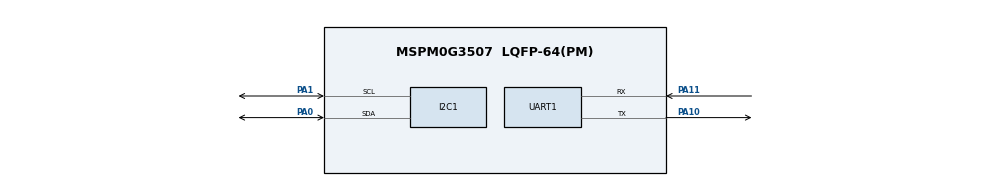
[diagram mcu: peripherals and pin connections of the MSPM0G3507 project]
/**
 * These arguments were used when this file was generated. They will be automatically applied on subsequent loads
 * via the GUI or CLI. Run CLI with '--help' for additional information on how to override these arguments.
 * @cliArgs --device "MSPM0G350X" --part "Default" --package "LQFP-64(PM)" --product "mspm0_sdk@2.10.00.04"
 * @v2CliArgs --device "MSPM0G3507" --package "LQFP-64(PM)" --product "mspm0_sdk@2.10.00.04"
 * @versions {"tool":"1.26.2+4477"}
 */

/**
 * Import the modules used in this configuration.
 */
const GPIO   = scripting.addModule("/ti/driverlib/GPIO", {}, false);
const GPIO1  = GPIO.addInstance();
const GPIO2  = GPIO.addInstance();
const GPIO3  = GPIO.addInstance();
const GPIO4  = GPIO.addInstance();
const I2C    = scripting.addModule("/ti/driverlib/I2C", {}, false);
const I2C1   = I2C.addInstance();
const SYSCTL = scripting.addModule("/ti/driverlib/SYSCTL");
const UART   = scripting.addModule("/ti/driverlib/UART", {}, false);
const UART1  = UART.addInstance();

/**
 * Write custom configuration values to the imported modules.
 */
GPIO1.$name                              = "LED1";
GPIO1.port                               = "PORTB";
GPIO1.associatedPins[0].internalResistor = "PULL_DOWN";
GPIO1.associatedPins[0].$name            = "PIN_2";
GPIO1.associatedPins[0].assignedPin      = "3";

const Board = scripting.addModule("/ti/driverlib/Board", {}, false);

GPIO2.$name                              = "KEY";
GPIO2.port                               = "PORTA";
GPIO2.associatedPins[0].$name            = "PIN_18";
GPIO2.associatedPins[0].direction        = "INPUT";
GPIO2.associatedPins[0].internalResistor = "PULL_DOWN";
GPIO2.associatedPins[0].assignedPin      = "18";

GPIO3.$name                              = "GRAY";
GPIO3.port                               = "PORTA";
GPIO3.associatedPins.create(5);
GPIO3.associatedPins[0].$name            = "S1";
GPIO3.associatedPins[0].direction        = "INPUT";
GPIO3.associatedPins[0].internalResistor = "PULL_DOWN";
GPIO3.associatedPins[0].assignedPin      = "14";
GPIO3.associatedPins[1].$name            = "S2";
GPIO3.associatedPins[1].direction        = "INPUT";
GPIO3.associatedPins[1].internalResistor = "PULL_DOWN";
GPIO3.associatedPins[1].assignedPin      = "15";
GPIO3.associatedPins[2].$name            = "S3";
GPIO3.associatedPins[2].direction        = "INPUT";
GPIO3.associatedPins[2].internalResistor = "PULL_DOWN";
GPIO3.associatedPins[2].assignedPin      = "16";
GPIO3.associatedPins[3].$name            = "S4";
GPIO3.associatedPins[3].direction        = "INPUT";
GPIO3.associatedPins[3].internalResistor = "PULL_DOWN";
GPIO3.associatedPins[3].assignedPin      = "17";
GPIO3.associatedPins[4].$name            = "S5";
GPIO3.associatedPins[4].direction        = "INPUT";
GPIO3.associatedPins[4].internalResistor = "PULL_DOWN";
GPIO3.associatedPins[4].assignedPin      = "21";

GPIO4.$name                              = "MOTOR_I2C";
GPIO4.port                               = "PORTA";
GPIO4.associatedPins.create(2);
GPIO4.associatedPins[0].$name            = "SDA";
GPIO4.associatedPins[0].direction        = "OUTPUT";
GPIO4.associatedPins[0].internalResistor = "PULL_UP";
GPIO4.associatedPins[0].initialValue     = "SET";
GPIO4.associatedPins[0].assignedPin      = "13";
GPIO4.associatedPins[1].$name            = "SCL";
GPIO4.associatedPins[1].direction        = "OUTPUT";
GPIO4.associatedPins[1].internalResistor = "PULL_UP";
GPIO4.associatedPins[1].initialValue     = "SET";
GPIO4.associatedPins[1].assignedPin      = "12";

SYSCTL.forceDefaultClkConfig = true;
SYSCTL.clockTreeEn           = true;

I2C1.$name                     = "I2C_0";
I2C1.basicEnableController     = true;
I2C1.basicControllerBusSpeed   = 400000;
I2C1.advAnalogGlitchFilter     = "DISABLED";
I2C1.peripheral.$assign        = "I2C0";
I2C1.peripheral.sdaPin.$assign = "PA0";
I2C1.peripheral.sclPin.$assign = "PA1";

UART1.$name                    = "UART_0";
UART1.enableFIFO               = true;
UART1.enableDMARX              = false;
UART1.enableDMATX              = false;
UART1.targetBaudRate           = 115200;
UART1.enableInternalLoopback   = false;
UART1.rxFifoThreshold          = "DL_UART_RX_FIFO_LEVEL_1_2_FULL";
UART1.peripheral.$assign       = "UART0";
UART1.peripheral.rxPin.$assign = "PA11";
UART1.peripheral.txPin.$assign = "PA10";
